# PIC32MX695F512L register map
Vendor: Microchip
Registers are 32-bit, read-write, reset 0x0 unless marked. A register's access mark holds for its fields unless they carry their own. Addresses are absolute, and some are shared; only a register's first bit layout is shown; [hi:lo] are bit positions; {n}, {i} and the like mark numbered series.

## PCACHE
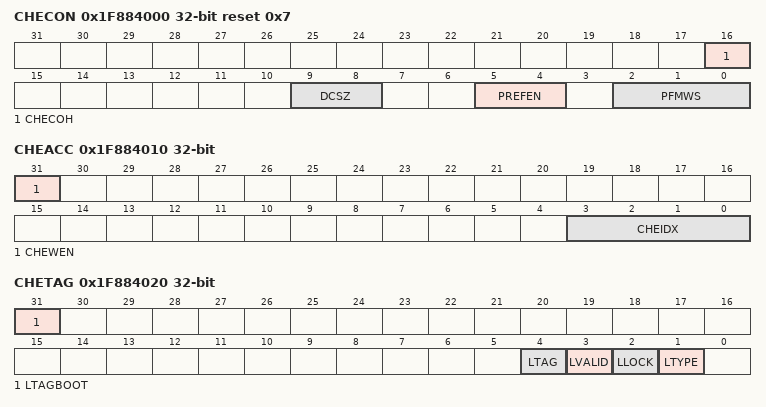
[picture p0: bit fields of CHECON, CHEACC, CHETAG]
0x1F884000 CHECON reset 0x7
  [16] CHECOH, [9:8] DCSZ, [5:4] PREFEN, [2:0] PFMWS
0x1F884010 CHEACC
  [31] CHEWEN, [3:0] CHEIDX
0x1F884020 CHETAG reset not defined — (power-on value 0xxxxxxxxxxxxxxxxxxxxxxxxxxx0010)
  [31] LTAGBOOT, [4] LTAG, [3] LVALID, [2] LLOCK, [1] LTYPE
0x1F884030 CHEMSK
  [15:5] LMASK
{0x1F884040+0x10*i} CHEW{i} reset not defined (i=0..3) — (power-on value xxxxxxxxxxxxxxxxxxxxxxxxxxxxxxxx)
0x1F884080 CHELRU
  [24:0] CHELRU
0x1F884090 CHEHIT reset not defined — (power-on value xxxxxxxxxxxxxxxxxxxxxxxxxxxxxxxx)
  [31:0] CHEHIT — (can only be cleared)
0x1F8840A0 CHEMIS reset not defined — (power-on value xxxxxxxxxxxxxxxxxxxxxxxxxxxxxxxx)
  [31:0] CHEMIS — (can only be cleared)
0x1F8840C0 CHEPFABT reset not defined — (power-on value xxxxxxxxxxxxxxxxxxxxxxxxxxxxxxxx)
  [31:0] CHEPFABT — (can only be cleared)

## USB
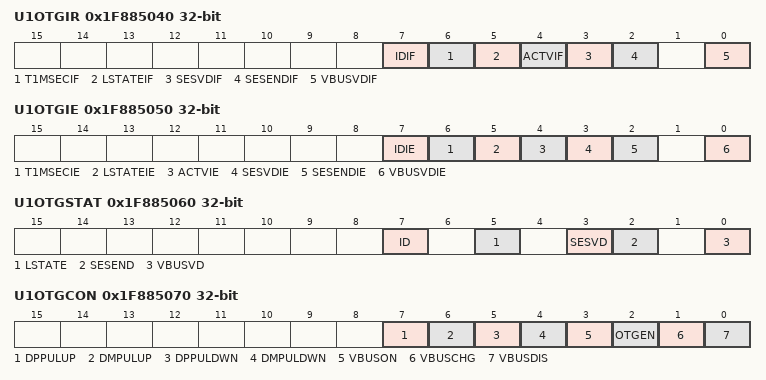
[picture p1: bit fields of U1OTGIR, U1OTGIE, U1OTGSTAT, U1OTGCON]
0x1F885040 U1OTGIR
  [7] IDIF, [6] T1MSECIF, [5] LSTATEIF, [4] ACTVIF, [3] SESVDIF, [2] SESENDIF, [0] VBUSVDIF
0x1F885050 U1OTGIE
  [7] IDIE, [6] T1MSECIE, [5] LSTATEIE, [4] ACTVIE, [3] SESVDIE, [2] SESENDIE, [0] VBUSVDIE
0x1F885060 U1OTGSTAT
  [7] ID, [5] LSTATE, [3] SESVD, [2] SESEND, [0] VBUSVD
0x1F885070 U1OTGCON
  [7] DPPULUP, [6] DMPULUP, [5] DPPULDWN, [4] DMPULDWN, [3] VBUSON, [2] OTGEN, [1] VBUSCHG, [0] VBUSDIS
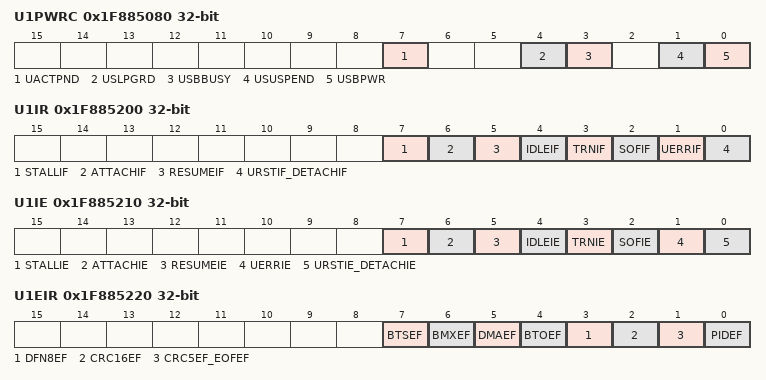
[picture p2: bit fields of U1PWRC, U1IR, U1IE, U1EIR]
0x1F885080 U1PWRC reset not defined — (power-on value ------------------------0--0x-00)
  [7] UACTPND ro, [4] USLPGRD, [3] USBBUSY, [1] USUSPEND, [0] USBPWR
0x1F885200 U1IR
  [7] STALLIF, [6] ATTACHIF, [5] RESUMEIF, [4] IDLEIF, [3] TRNIF, [2] SOFIF, [1] UERRIF, [0] URSTIF_DETACHIF
0x1F885210 U1IE
  [7] STALLIE, [6] ATTACHIE, [5] RESUMEIE, [4] IDLEIE, [3] TRNIE, [2] SOFIE, [1] UERRIE, [0] URSTIE_DETACHIE
0x1F885220 U1EIR
  [7] BTSEF, [6] BMXEF, [5] DMAEF, [4] BTOEF, [3] DFN8EF, [2] CRC16EF, [1] CRC5EF_EOFEF, [0] PIDEF
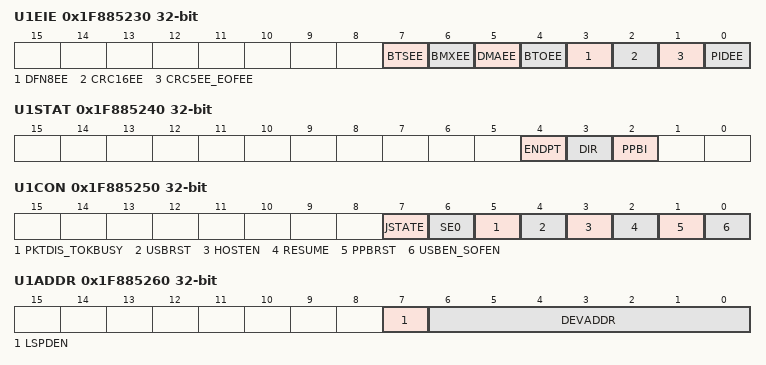
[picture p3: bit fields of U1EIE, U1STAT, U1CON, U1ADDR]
0x1F885230 U1EIE reset not defined — (power-on value ------------------------0000000x)
  [7] BTSEE, [6] BMXEE, [5] DMAEE, [4] BTOEE, [3] DFN8EE, [2] CRC16EE, [1] CRC5EE_EOFEE, [0] PIDEE
0x1F885240 U1STAT ro reset not defined
  [4] ENDPT, [3] DIR, [2] PPBI
0x1F885250 U1CON
  [7] JSTATE, [6] SE0, [5] PKTDIS_TOKBUSY, [4] USBRST, [3] HOSTEN, [2] RESUME, [1] PPBRST, [0] USBEN_SOFEN
0x1F885260 U1ADDR
  [7] LSPDEN, [6:0] DEVADDR
0x1F885270 U1BDTP1
  [7:1] BDTPTRL
0x1F885280 U1FRML ro reset not defined
  [7:0] FRML
0x1F885290 U1FRMH ro reset not defined
  [2:0] FRMH
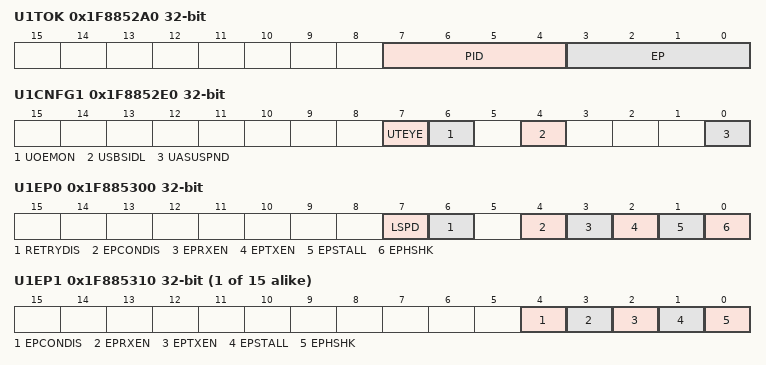
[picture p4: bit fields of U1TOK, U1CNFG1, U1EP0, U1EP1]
0x1F8852A0 U1TOK
  [7:4] PID, [3:0] EP
0x1F8852B0 U1SOF
  [7:0] CNT
0x1F8852C0 U1BDTP2
  [7:0] BDTPTRH
0x1F8852D0 U1BDTP3
  [7:0] BDTPTRU
0x1F8852E0 U1CNFG1 reset not defined — (power-on value ------------------------xxxx-00x)
  [7] UTEYE, [6] UOEMON, [4] USBSIDL, [0] UASUSPND
0x1F885300 U1EP0
  [7] LSPD, [6] RETRYDIS, [4] EPCONDIS, [3] EPRXEN, [2] EPTXEN, [1] EPSTALL, [0] EPHSHK
{0x1F885300+0x10*i} U1EP{i} (i=1..15)
  [4] EPCONDIS, [3] EPRXEN, [2] EPTXEN, [1] EPSTALL, [0] EPHSHK

## TDAA_Ports
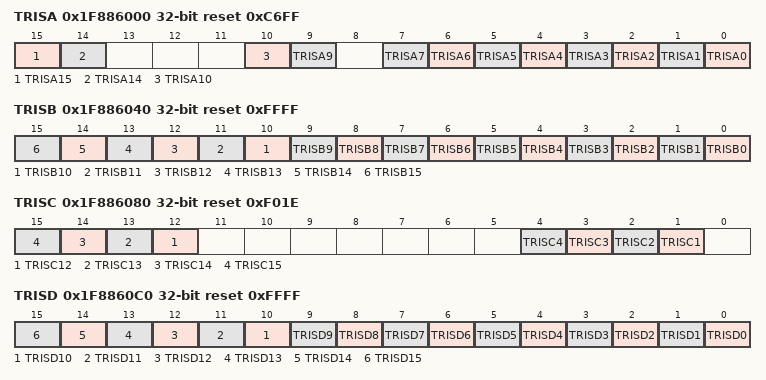
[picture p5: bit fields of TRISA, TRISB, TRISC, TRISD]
0x1F886000 TRISA reset 0xC6FF
  [15] TRISA15, [14] TRISA14, [10] TRISA10, [9] TRISA9, [n] TRISA{n} (n=0..7)
0x1F886040 TRISB reset 0xFFFF
  [n] TRISB{n} (n=0..15)
0x1F886080 TRISC reset 0xF01E
  [n] TRISC{n} (n=12..15), [n] TRISC{n} (n=1..4)
0x1F8860C0 TRISD reset 0xFFFF
  [n] TRISD{n} (n=0..15)
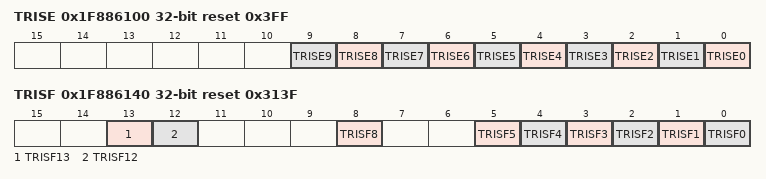
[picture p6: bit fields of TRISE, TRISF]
0x1F886100 TRISE reset 0x3FF
  [n] TRISE{n} (n=0..9)
0x1F886140 TRISF reset 0x313F
  [13] TRISF13, [12] TRISF12, [8] TRISF8, [n] TRISF{n} (n=0..5)

## PORTA
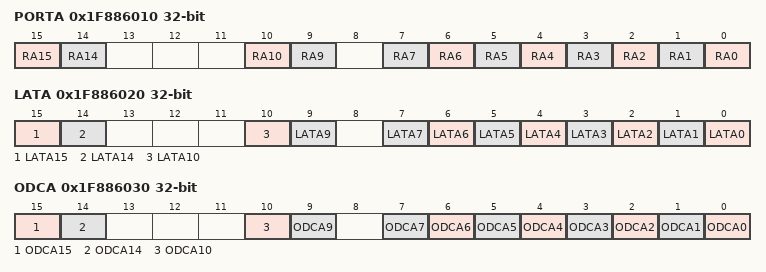
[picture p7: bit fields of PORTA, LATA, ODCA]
0x1F886010 PORTA reset not defined — (power-on value ----------------xx---xx-xxxxxxxx)
  [15] RA15, [14] RA14, [10] RA10, [9] RA9, [n] RA{n} (n=0..7)
0x1F886020 LATA reset not defined — (power-on value ----------------xx---xx-xxxxxxxx)
  [15] LATA15, [14] LATA14, [10] LATA10, [9] LATA9, [n] LATA{n} (n=0..7)
0x1F886030 ODCA
  [15] ODCA15, [14] ODCA14, [10] ODCA10, [9] ODCA9, [n] ODCA{n} (n=0..7)

## PORTB
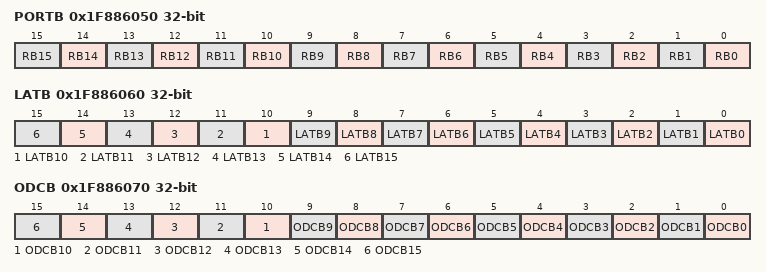
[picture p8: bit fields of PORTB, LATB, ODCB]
0x1F886050 PORTB reset not defined — (power-on value ----------------xxxxxxxxxxxxxxxx)
  [n] RB{n} (n=0..15)
0x1F886060 LATB reset not defined — (power-on value ----------------xxxxxxxxxxxxxxxx)
  [n] LATB{n} (n=0..15)
0x1F886070 ODCB
  [n] ODCB{n} (n=0..15)

## PORTC
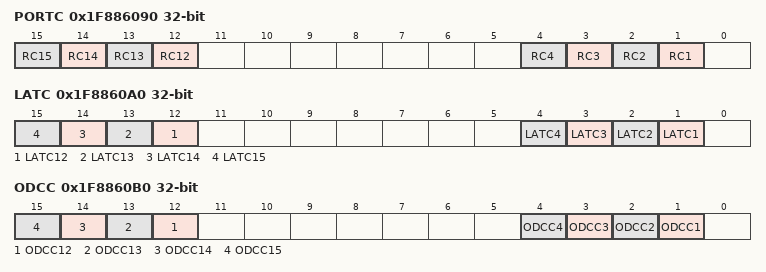
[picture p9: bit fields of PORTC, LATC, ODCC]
0x1F886090 PORTC reset not defined — (power-on value ----------------xxxx-------xxxx-)
  [n] RC{n} (n=12..15), [n] RC{n} (n=1..4)
0x1F8860A0 LATC reset not defined — (power-on value ----------------xxxx-------xxxx-)
  [n] LATC{n} (n=12..15), [n] LATC{n} (n=1..4)
0x1F8860B0 ODCC
  [n] ODCC{n} (n=12..15), [n] ODCC{n} (n=1..4)

## PORTD
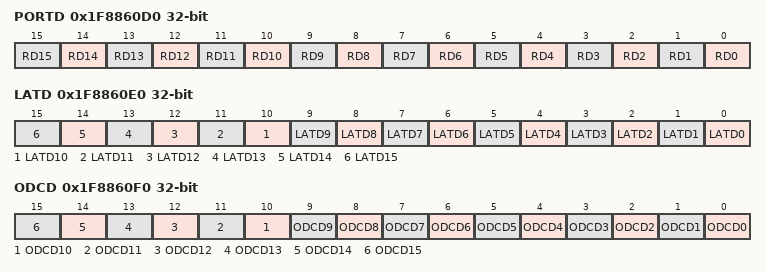
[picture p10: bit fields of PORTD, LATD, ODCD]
0x1F8860D0 PORTD reset not defined — (power-on value ----------------xxxxxxxxxxxxxxxx)
  [n] RD{n} (n=0..15)
0x1F8860E0 LATD reset not defined — (power-on value ----------------xxxxxxxxxxxxxxxx)
  [n] LATD{n} (n=0..15)
0x1F8860F0 ODCD
  [n] ODCD{n} (n=0..15)

## PORTE
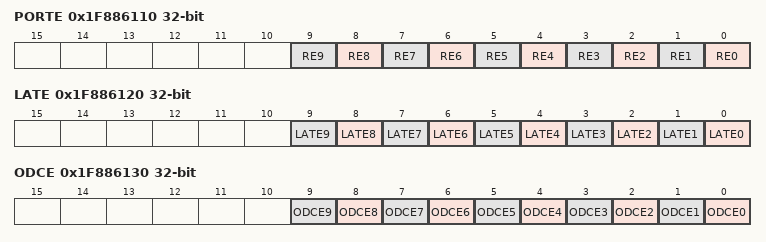
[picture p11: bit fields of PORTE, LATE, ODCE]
0x1F886110 PORTE reset not defined — (power-on value ----------------------xxxxxxxxxx)
  [n] RE{n} (n=0..9)
0x1F886120 LATE reset not defined — (power-on value ----------------------xxxxxxxxxx)
  [n] LATE{n} (n=0..9)
0x1F886130 ODCE
  [n] ODCE{n} (n=0..9)

## PORTF
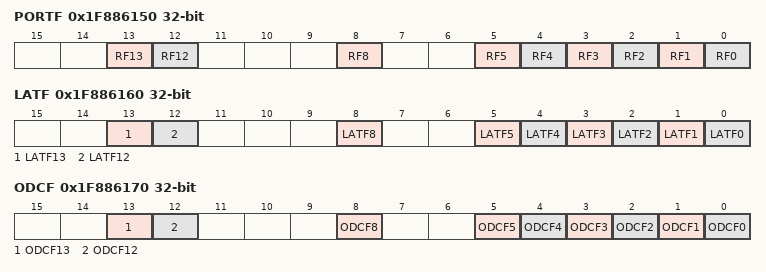
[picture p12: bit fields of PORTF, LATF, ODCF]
0x1F886150 PORTF reset not defined — (power-on value ------------------xx---x--xxxxxx)
  [13] RF13, [12] RF12, [8] RF8, [n] RF{n} (n=0..5)
0x1F886160 LATF reset not defined — (power-on value ------------------xx---x--xxxxxx)
  [13] LATF13, [12] LATF12, [8] LATF8, [n] LATF{n} (n=0..5)
0x1F886170 ODCF
  [13] ODCF13, [12] ODCF12, [8] ODCF8, [n] ODCF{n} (n=0..5)

## TDAA_PortG
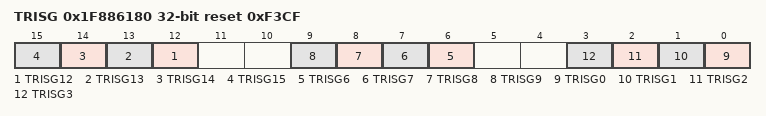
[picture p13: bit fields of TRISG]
0x1F886180 TRISG reset 0xF3CF
  [n] TRISG{n} (n=12..15), [n] TRISG{n} (n=6..9), [n] TRISG{n} (n=0..3)

## PORTG
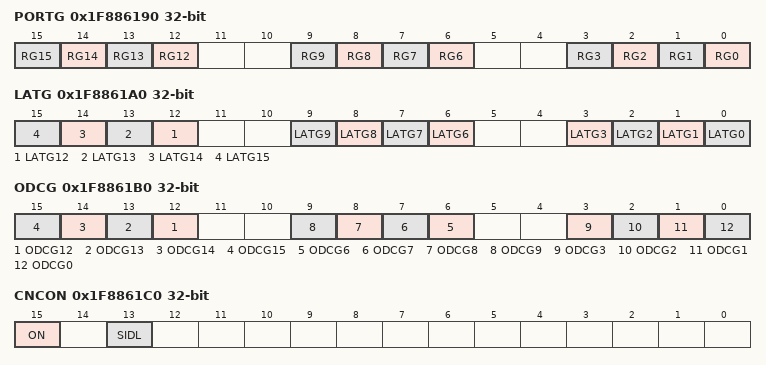
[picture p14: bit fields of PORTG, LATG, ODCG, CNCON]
0x1F886190 PORTG reset not defined — (power-on value ----------------xxxx--xxxx--xxxx)
  [n] RG{n} (n=12..15), [n] RG{n} (n=6..9), [n] RG{n} (n=0..3)
0x1F8861A0 LATG reset not defined — (power-on value ----------------xxxx--xxxx--xxxx)
  [n] LATG{n} (n=12..15), [n] LATG{n} (n=6..9), [3] LATG3 ro, [2] LATG2 ro, [1] LATG1, [0] LATG0
0x1F8861B0 ODCG
  [n] ODCG{n} (n=12..15), [n] ODCG{n} (n=6..9), [3] ODCG3 ro, [2] ODCG2 ro, [1] ODCG1, [0] ODCG0
0x1F8861C0 CNCON
  [15] ON, [13] SIDL
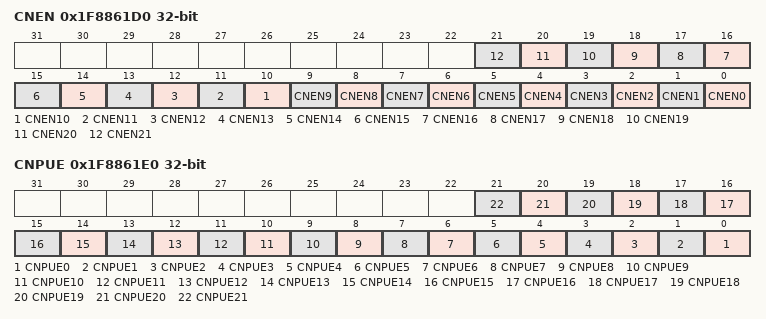
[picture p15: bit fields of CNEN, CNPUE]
0x1F8861D0 CNEN
  [n] CNEN{n} (n=0..21)
0x1F8861E0 CNPUE
  [n] CNPUE{n} (n=0..21)
